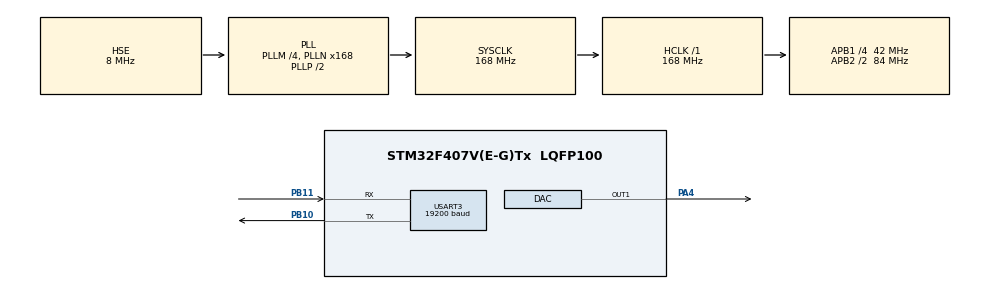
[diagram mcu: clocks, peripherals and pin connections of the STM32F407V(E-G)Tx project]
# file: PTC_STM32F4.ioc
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DAC.DAC_Trigger=DAC_TRIGGER_T6_TRGO
DAC.WaveGeneration=DISABLE
Dma.DAC1.0.Direction=DMA_MEMORY_TO_PERIPH
Dma.DAC1.0.FIFOMode=DMA_FIFOMODE_DISABLE
Dma.DAC1.0.Instance=DMA1_Stream5
Dma.DAC1.0.MemDataAlignment=DMA_MDATAALIGN_BYTE
Dma.DAC1.0.MemInc=DMA_MINC_ENABLE
Dma.DAC1.0.Mode=DMA_CIRCULAR
Dma.DAC1.0.PeriphDataAlignment=DMA_PDATAALIGN_BYTE
Dma.DAC1.0.PeriphInc=DMA_PINC_DISABLE
Dma.DAC1.0.Priority=DMA_PRIORITY_LOW
Dma.Request0=DAC1
Mcu.Family=STM32F4
Mcu.Name=STM32F407V(E-G)Tx
Mcu.Package=LQFP100
NVIC.DMA1_Stream5_IRQn=true\:0\:0\:false\:false\:true\:false\:true
NVIC.PriorityGroup=NVIC_PRIORITYGROUP_4
NVIC.USART3_IRQn=true\:0\:0\:false\:false\:true\:true\:true
PA13.Mode=Serial_Wire
PA13.Signal=SYS_JTMS-SWDIO
PA14.Mode=Serial_Wire
PA14.Signal=SYS_JTCK-SWCLK
PA4.Signal=COMP_DAC1_group
PB10.Mode=Asynchronous
PB10.Signal=USART3_TX
PB11.Mode=Asynchronous
PB11.Signal=USART3_RX
PC14-OSC32_IN.Mode=LSE-External-Oscillator
PC14-OSC32_IN.Signal=RCC_OSC32_IN
PC15-OSC32_OUT.Mode=LSE-External-Oscillator
PC15-OSC32_OUT.Signal=RCC_OSC32_OUT
PH0-OSC_IN.Mode=HSE-External-Oscillator
PH0-OSC_IN.Signal=RCC_OSC_IN
PH1-OSC_OUT.Mode=HSE-External-Oscillator
PH1-OSC_OUT.Signal=RCC_OSC_OUT
ProjectManager.HeapSize=0x200
ProjectManager.StackSize=0x400
ProjectManager.TargetToolchain=MDK-ARM V5
RCC.48MHZClocksFreq_Value=42000000
RCC.AHBFreq_Value=168000000
RCC.APB1CLKDivider=RCC_HCLK_DIV4
RCC.APB1Freq_Value=42000000
RCC.APB1TimFreq_Value=84000000
RCC.APB2CLKDivider=RCC_HCLK_DIV2
RCC.APB2Freq_Value=84000000
RCC.APB2TimFreq_Value=168000000
RCC.CortexFreq_Value=168000000
RCC.HCLKFreq_Value=168000000
RCC.HSE_VALUE=8000000
RCC.HSI_VALUE=16000000
RCC.PLLM=4
RCC.PLLN=168
RCC.PLLQ=8
RCC.PLLSourceVirtual=RCC_PLLSOURCE_HSE
RCC.SYSCLKFreq_VALUE=168000000
RCC.SYSCLKSource=RCC_SYSCLKSOURCE_PLLCLK
RCC.VCOOutputFreq_Value=336000000
SH.COMP_DAC1_group.0=DAC_OUT1,DAC_OUT1
TIM6.AutoReloadPreload=TIM_AUTORELOAD_PRELOAD_ENABLE
TIM6.Period=5017-1
TIM6.Prescaler=1-1
TIM6.TIM_MasterOutputTrigger=TIM_TRGO_UPDATE
USART3.BaudRate=19200
USART3.VirtualMode=VM_ASYNC
VP_RTC_VS_RTC_Activate.Mode=RTC_Enabled
VP_RTC_VS_RTC_Calendar.Mode=RTC_Calendar
VP_TIM6_VS_ClockSourceINT.Mode=Enable_Timer
board=custom

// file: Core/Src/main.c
/* USER CODE BEGIN Header */
/**
  ******************************************************************************
  * @file           : main.c
  * @brief          : Main program body
  ******************************************************************************
  * @attention
  *
  * <h2><center>&copy; Copyright (c) 2021 STMicroelectronics.
  * All rights reserved.</center></h2>
  *
  * This software component is licensed by ST under BSD 3-Clause license,
  * the "License"; You may not use this file except in compliance with the
  * License. You may obtain a copy of the License at:
  *                        opensource.org/licenses/BSD-3-Clause
  *
  ******************************************************************************
  */
/* USER CODE END Header */
#include "main.h"

/* USER CODE BEGIN Includes */
#include <stdio.h> //printf()
#include <string.h>

#include "PTC_decodeCmd.h"
#include "PTC_UART3.h"
#include "UART0_RingBuffer_lib.h"
#include "PTC_geter_cmd.h"
#include "PTC_convertion.h"

#define CLK_APB1_P 42000000
#define CLK_APB1_T 84000000
#define CLK_APB2_P 84000000
#define CLK_APB2_T 168000000

#define DAC_BUF_LEN 65
/* USER CODE END Includes */

/* USER CODE BEGIN PM */
RTC_TimeTypeDef currentTime;
/* USER CODE END PM */

DAC_HandleTypeDef hdac;
DMA_HandleTypeDef hdma_dac1;

RTC_HandleTypeDef hrtc;

TIM_HandleTypeDef htim6;

UART_HandleTypeDef huart3;

void SystemClock_Config(void);
static void MX_GPIO_Init(void);
static void MX_DMA_Init(void);
static void MX_DAC_Init(void);
static void MX_TIM6_Init(void);
static void MX_USART3_UART_Init(void);
static void MX_RTC_Init(void);
/* USER CODE BEGIN PFP */
#ifdef __GNUC__
  /* With GCC, small printf (option LD Linker->Libraries->Small printf
     set to 'Yes') calls __io_putchar() */
  #define PUTCHAR_PROTOTYPE int __io_putchar(int ch)
#else
  #define PUTCHAR_PROTOTYPE int fputc(int ch, FILE *f)
#endif /* __GNUC__ */
/* USER CODE END PFP */

/* USER CODE BEGIN 0 */
//Signaux sonore :
typedef struct Music_note Music_note;
struct Music_note {
  uint8_t code ;
  float   freq ;
};

const uint8_t myDAC_Signal[DAC_BUF_LEN] = {127, 139,151,163,175,186,197,207,216,225,232,239,244,248,251,253,254,253,251,248,244,239,232,225,216,207,197,186,175,163,151,139,127,115,103,91,79,68,57,47,38,29,22,15,10,6,3,1,0,1,3,6,10,15,22,29,38,47,57,68,79,91,103,115,127};
char rx_Buf = 0;
char tx_Buf[32]  = "Start\r\n";
char chaine_courante[32] = {0};

//en lien avec la generation de son
char Code_frequence;
int  Timer_freq;
unsigned int Duree_son;
unsigned int Duree_silence;
char Nombre_bips;
char Sound_Loop_Enable = 0;
char Etat_Bip = 0;
unsigned long Temp_init;
/*

Music_note DO3  ; DO3.code  = 1 ; DO3.freq  = 261.6    ;       //4940
Music_note RE3  ; RE3.code  = 2 ; RE3.freq  = 293.7    ;       //4400
Music_note MI3  ; MI3.code  = 3 ; MI3.freq  = 329.7    ;       //3913
Music_note FA3  ; FA3.code  = 4 ; FA3.freq  = 349.2    ;       //3700
Music_note SOL3 ; SOL3.code = 5 ; SOL3.freq = 392.0    ;       //3297
Music_note LA3  ; LA3.code  = 6 ; LA3.freq  = 440.Nombre_dips0    ;       //2937
Music_note SI3  ; SI3.code  = 7 ; SI3.freq  = 493.9    ;       //2617

Music_note DO4  ; DO4.code  = 8 ; DO4.freq  = 2.0*261.6;       //4940/2 = 2470
Music_note RE4  ; RE4.code  = 9 ; RE4.freq  = 2.0*293.7;       //4400/2 = 2200
Music_note MI4  ; MI4.code  = 10; MI4.freq  = 2.0*329.7;       //3913/2 = 1957
Music_note FA4  ; FA4.code  = 11; FA4.freq  = 2.0*349.2;       //3700/2 = 1850
Music_note SOL4 ; SOL4.code = 12; SOL4.freq = 2.0*392.0;       //3297/2 = 1649
Music_note LA4  ; LA4.code  = 13; LA4.freq  = 2.0*440.0;       //2937/2 = 1468
Music_note SI4  ; SI4.code  = 14; SI4.freq  = 2.0*493.9;       //2617/2 = 1308

Music_note DO5  ; DO5.code  = 15; DO5.freq  = 4.0*261.6;       //4940/4 = 1235
Music_note RE5  ; RE5.code  = 16; RE5.freq  = 4.0*293.7;       //4400/4 = 1100
Music_note MI5  ; MI5.code  = 17; MI5.freq  = 4.0*329.7;       //3913/4 = 978
Music_note FA5  ; FA5.code  = 18; FA5.freq  = 4.0*349.2;       //3700/4 = 925
Music_note SOL5 ; SOL5.code = 19; SOL5.freq = 4.0*392.0;       //3297/4 = 824
Music_note LA5  ; LA5.code  = 20; LA5.freq  = 4.0*440.0;       //2937/4 = 734
Music_note SI5  ; SI5.code  = 21; SI5.freq  = 4.0*493.9;       //2617/4 = 654
*/

/**
* @brief Configure la frequence du dac
* @param freq: Frequence du sinus souhaite en sortie du dac
* @retval None
*/
void Set_freq_DAC0(uint32_t freq){
	if (freq == 0){
		HAL_DAC_Stop_DMA(&hdac ,DAC1_CHANNEL_1);
	}
	else {
		HAL_DAC_Start_DMA(&hdac, DAC1_CHANNEL_1, (uint32_t *)myDAC_Signal, 65, DAC_ALIGN_8B_R);
		//htim6.Init.Period = CLK_APB1_T/(DAC_BUF_LEN*freq)-1;
		htim6.Init.Period = freq;
		if (HAL_TIM_Base_Init(&htim6) != HAL_OK)
		{
    Error_Handler();
		}
	}

}

void decodage_commande(char *Pchaine_courante){
	char commande[10] ={0};
	get_commande(Pchaine_courante,commande);
	if (strcmp(commande,"SD") == 0){
		Cmd_epreuve_SD_stm32(Pchaine_courante);
	}
	RAZ_str(Pchaine_courante);
}

void Sound_Callback(){
    if (Nombre_bips != 0) {
        if (!Etat_Bip) { //si la led est eteinte
            if ((HAL_GetTick() - Temp_init) > Duree_silence) {
                Set_freq_DAC0(Timer_freq); //On allume la LED
                Etat_Bip = 1; //on signal l'etat de la LED
                Temp_init = HAL_GetTick(); //Nouvelle reference de temps
            }
        }
        else {
			long tmp = HAL_GetTick() - Temp_init; //debug
            if ((HAL_GetTick() - Temp_init) > Duree_son) {
                Set_freq_DAC0(0); //On eteind la LED
                Etat_Bip = 0; //on signal l'etat de la LED
                Temp_init = HAL_GetTick(); //Nouvelle reference de temps
                Nombre_bips--; //On decremente le nombre de cycle
                if (Nombre_bips == 0)
                    Sound_Loop_Enable = 0;
            }
        }
    }
}

void HAL_UART_TxCpltCallback(UART_HandleTypeDef *huart)
{
  __NOP();
}

/* USER CODE END 0 */

int main(void)
{

  /* MCU Configuration--------------------------------------------------------*/

  /* Reset of all peripherals, Initializes the Flash interface and the Systick. */
  HAL_Init();

  /* Configure the system clock */
  SystemClock_Config();

  /* Initialize all configured peripherals */
  MX_GPIO_Init();
  MX_DMA_Init();
  MX_DAC_Init();
  MX_TIM6_Init();
  MX_USART3_UART_Init();
  MX_RTC_Init();
  /* USER CODE BEGIN 2 */
	init_Serial_Buffer();
	HAL_TIM_Base_Start(&htim6);
  HAL_UART_Receive_IT(&huart3, (uint8_t *)&rx_Buf,1);
	HAL_UART_Transmit(&huart3, (uint8_t *)tx_Buf, strlen(tx_Buf), 100);

	while(rx_Buf != 0x73){}
	HAL_UART_Transmit(&huart3, (uint8_t *)"t", 1, 100);
	Rx_chaine(chaine_courante);
	RAZ_str(chaine_courante);

  /* USER CODE END 2 */

  /* Infinite loop */
  /* USER CODE BEGIN WHILE */
  while (1)
		{
		if (Rx_chaine(chaine_courante) == 1){
			__NOP();
			decodage_commande(chaine_courante);
		}
		if (Sound_Loop_Enable == 1) {
			Sound_Callback();
		}
    /* USER CODE END WHILE */

  }
}

void SystemClock_Config(void)
{
  RCC_OscInitTypeDef RCC_OscInitStruct = {0};
  RCC_ClkInitTypeDef RCC_ClkInitStruct = {0};
  RCC_PeriphCLKInitTypeDef PeriphClkInitStruct = {0};

  /** Configure the main internal regulator output voltage
  */
  __HAL_RCC_PWR_CLK_ENABLE();
  __HAL_PWR_VOLTAGESCALING_CONFIG(PWR_REGULATOR_VOLTAGE_SCALE1);
  /** Initializes the RCC Oscillators according to the specified parameters
  * in the RCC_OscInitTypeDef structure.
  */
  RCC_OscInitStruct.OscillatorType = RCC_OSCILLATORTYPE_LSI|RCC_OSCILLATORTYPE_HSE;
  RCC_OscInitStruct.HSEState = RCC_HSE_ON;
  RCC_OscInitStruct.LSIState = RCC_LSI_ON;
  RCC_OscInitStruct.PLL.PLLState = RCC_PLL_ON;
  RCC_OscInitStruct.PLL.PLLSource = RCC_PLLSOURCE_HSE;
  RCC_OscInitStruct.PLL.PLLM = 4;
  RCC_OscInitStruct.PLL.PLLN = 168;
  RCC_OscInitStruct.PLL.PLLP = RCC_PLLP_DIV2;
  RCC_OscInitStruct.PLL.PLLQ = 8;
  if (HAL_RCC_OscConfig(&RCC_OscInitStruct) != HAL_OK)
  {
    Error_Handler();
  }
  /** Initializes the CPU, AHB and APB buses clocks
  */
  RCC_ClkInitStruct.ClockType = RCC_CLOCKTYPE_HCLK|RCC_CLOCKTYPE_SYSCLK
                              |RCC_CLOCKTYPE_PCLK1|RCC_CLOCKTYPE_PCLK2;
  RCC_ClkInitStruct.SYSCLKSource = RCC_SYSCLKSOURCE_PLLCLK;
  RCC_ClkInitStruct.AHBCLKDivider = RCC_SYSCLK_DIV1;
  RCC_ClkInitStruct.APB1CLKDivider = RCC_HCLK_DIV4;
  RCC_ClkInitStruct.APB2CLKDivider = RCC_HCLK_DIV2;

  if (HAL_RCC_ClockConfig(&RCC_ClkInitStruct, FLASH_LATENCY_5) != HAL_OK)
  {
    Error_Handler();
  }
  PeriphClkInitStruct.PeriphClockSelection = RCC_PERIPHCLK_RTC;
  PeriphClkInitStruct.RTCClockSelection = RCC_RTCCLKSOURCE_LSI;
  if (HAL_RCCEx_PeriphCLKConfig(&PeriphClkInitStruct) != HAL_OK)
  {
    Error_Handler();
  }
}

static void MX_DAC_Init(void)
{

  DAC_ChannelConfTypeDef sConfig = {0};

  /** DAC Initialization
  */
  hdac.Instance = DAC;
  if (HAL_DAC_Init(&hdac) != HAL_OK)
  {
    Error_Handler();
  }
  /** DAC channel OUT1 config
  */
  sConfig.DAC_Trigger = DAC_TRIGGER_T6_TRGO;
  sConfig.DAC_OutputBuffer = DAC_OUTPUTBUFFER_ENABLE;
  if (HAL_DAC_ConfigChannel(&hdac, &sConfig, DAC_CHANNEL_1) != HAL_OK)
  {
    Error_Handler();
  }

}

static void MX_RTC_Init(void)
{

  RTC_TimeTypeDef sTime = {0};
  RTC_DateTypeDef sDate = {0};

  /** Initialize RTC Only
  */
  hrtc.Instance = RTC;
  hrtc.Init.HourFormat = RTC_HOURFORMAT_24;
  hrtc.Init.AsynchPrediv = 127;
  hrtc.Init.SynchPrediv = 255;
  hrtc.Init.OutPut = RTC_OUTPUT_DISABLE;
  hrtc.Init.OutPutPolarity = RTC_OUTPUT_POLARITY_HIGH;
  hrtc.Init.OutPutType = RTC_OUTPUT_TYPE_OPENDRAIN;
  if (HAL_RTC_Init(&hrtc) != HAL_OK)
  {
    Error_Handler();
  }

  /** Initialize RTC and set the Time and Date
  */
  sTime.Hours = 0x0;
  sTime.Minutes = 0x0;
  sTime.Seconds = 0x0;
  sTime.DayLightSaving = RTC_DAYLIGHTSAVING_NONE;
  sTime.StoreOperation = RTC_STOREOPERATION_RESET;
  if (HAL_RTC_SetTime(&hrtc, &sTime, RTC_FORMAT_BCD) != HAL_OK)
  {
    Error_Handler();
  }
  sDate.WeekDay = RTC_WEEKDAY_MONDAY;
  sDate.Month = RTC_MONTH_JANUARY;
  sDate.Date = 0x1;
  sDate.Year = 0x0;

  if (HAL_RTC_SetDate(&hrtc, &sDate, RTC_FORMAT_BCD) != HAL_OK)
  {
    Error_Handler();
  }

}

static void MX_TIM6_Init(void)
{

  TIM_MasterConfigTypeDef sMasterConfig = {0};

  htim6.Instance = TIM6;
  htim6.Init.Prescaler = 1-1;
  htim6.Init.CounterMode = TIM_COUNTERMODE_UP;
  htim6.Init.Period = 5017-1;
  htim6.Init.AutoReloadPreload = TIM_AUTORELOAD_PRELOAD_ENABLE;
  if (HAL_TIM_Base_Init(&htim6) != HAL_OK)
  {
    Error_Handler();
  }
  sMasterConfig.MasterOutputTrigger = TIM_TRGO_UPDATE;
  sMasterConfig.MasterSlaveMode = TIM_MASTERSLAVEMODE_DISABLE;
  if (HAL_TIMEx_MasterConfigSynchronization(&htim6, &sMasterConfig) != HAL_OK)
  {
    Error_Handler();
  }

}

static void MX_USART3_UART_Init(void)
{

  huart3.Instance = USART3;
  huart3.Init.BaudRate = 19200;
  huart3.Init.WordLength = UART_WORDLENGTH_8B;
  huart3.Init.StopBits = UART_STOPBITS_1;
  huart3.Init.Parity = UART_PARITY_NONE;
  huart3.Init.Mode = UART_MODE_TX_RX;
  huart3.Init.HwFlowCtl = UART_HWCONTROL_NONE;
  huart3.Init.OverSampling = UART_OVERSAMPLING_16;
  if (HAL_UART_Init(&huart3) != HAL_OK)
  {
    Error_Handler();
  }

}

static void MX_DMA_Init(void)
{

  /* DMA controller clock enable */
  __HAL_RCC_DMA1_CLK_ENABLE();

  /* DMA interrupt init */
  /* DMA1_Stream5_IRQn interrupt configuration */
  HAL_NVIC_SetPriority(DMA1_Stream5_IRQn, 0, 0);
  HAL_NVIC_EnableIRQ(DMA1_Stream5_IRQn);

}

static void MX_GPIO_Init(void)
{

  /* GPIO Ports Clock Enable */
  __HAL_RCC_GPIOC_CLK_ENABLE();
  __HAL_RCC_GPIOH_CLK_ENABLE();
  __HAL_RCC_GPIOA_CLK_ENABLE();
  __HAL_RCC_GPIOB_CLK_ENABLE();

}

void Error_Handler(void)
{
   __disable_irq();
  while (1)
  {
  }
}

/************************ (C) COPYRIGHT STMicroelectronics *****END OF FILE****/
